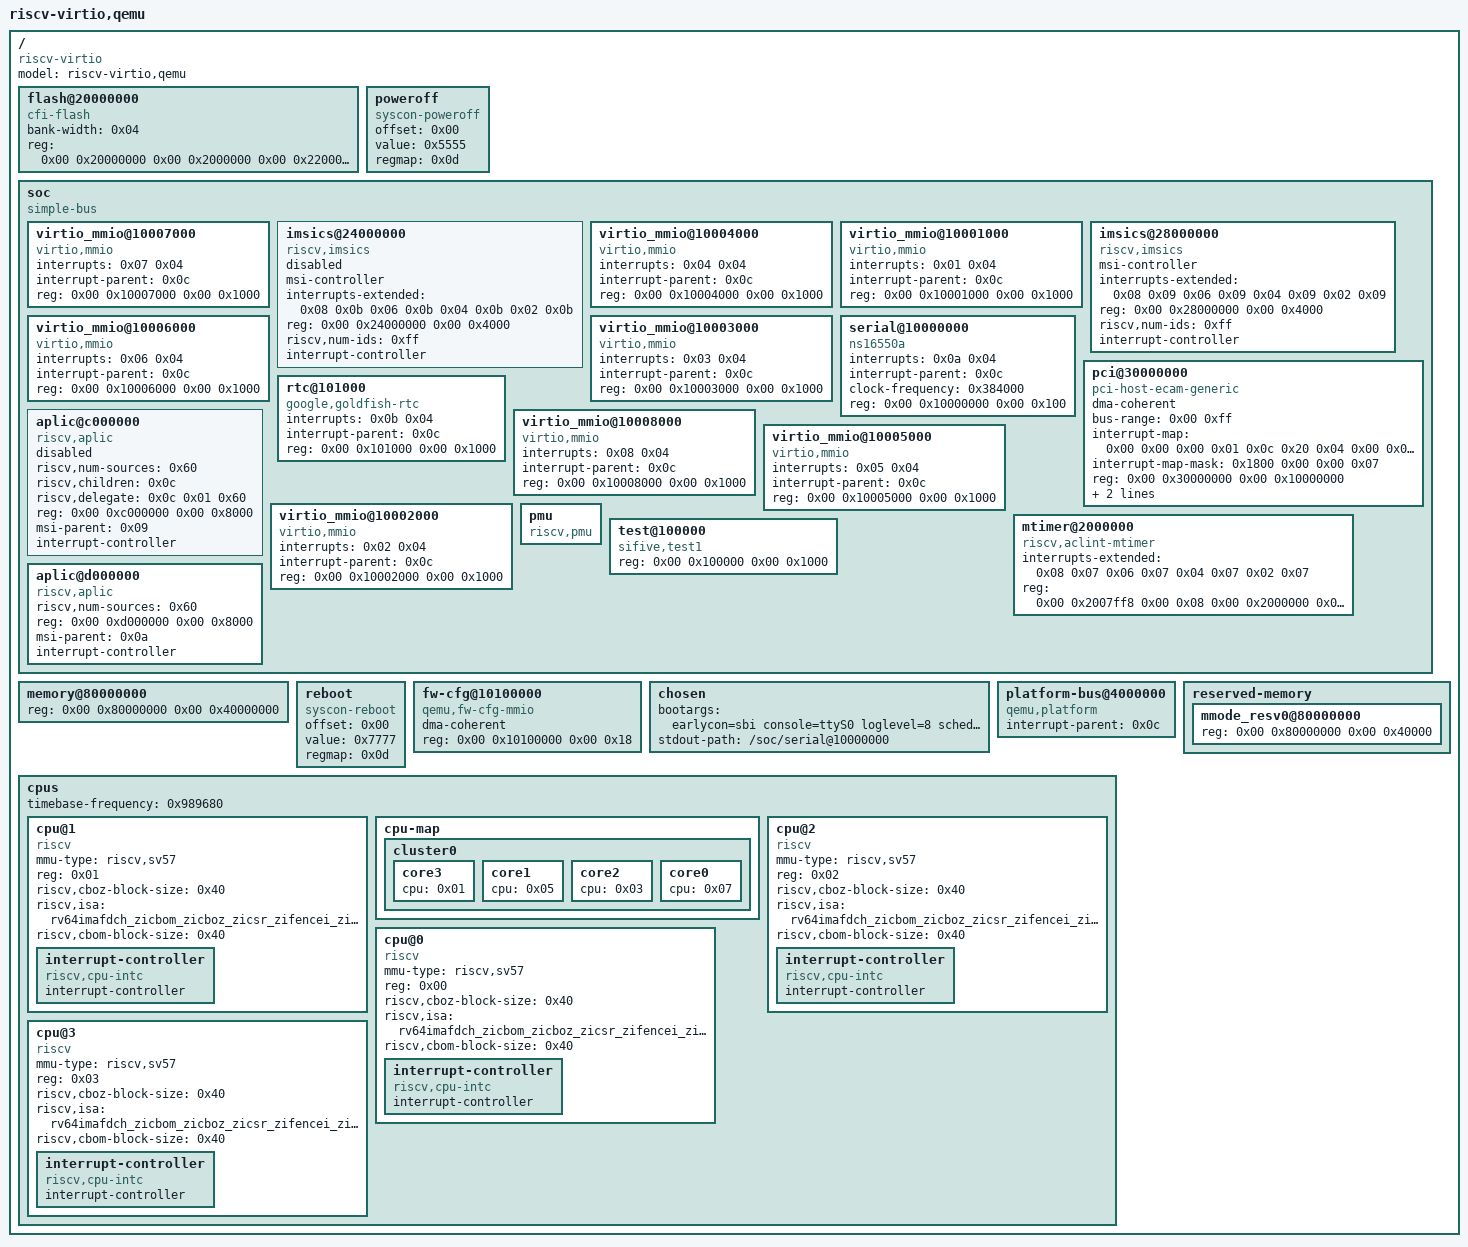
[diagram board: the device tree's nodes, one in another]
/dts-v1/;

/ {
	#address-cells = <0x02>;
	model = "riscv-virtio,qemu";
	#size-cells = <0x02>;
	compatible = "riscv-virtio";

	flash@20000000 {
		bank-width = <0x04>;
		compatible = "cfi-flash";
		reg = <0x00 0x20000000 0x00 0x2000000 0x00 0x22000000 0x00 0x2000000>;
	};

	poweroff {
		offset = <0x00>;
		compatible = "syscon-poweroff";
		value = <0x5555>;
		regmap = <0x0d>;
	};

	soc {
		#address-cells = <0x02>;
		#size-cells = <0x02>;
		compatible = "simple-bus";
		ranges;

		virtio_mmio@10007000 {
			interrupts = <0x07 0x04>;
			interrupt-parent = <0x0c>;
			compatible = "virtio,mmio";
			reg = <0x00 0x10007000 0x00 0x1000>;
		};

		imsics@24000000 {
			msi-controller;
			interrupts-extended = <0x08 0x0b 0x06 0x0b 0x04 0x0b 0x02 0x0b>;
			compatible = "riscv,imsics";
			#interrupt-cells = <0x00>;
			status = "disabled";
			reg = <0x00 0x24000000 0x00 0x4000>;
			riscv,num-ids = <0xff>;
			phandle = <0x09>;
			interrupt-controller;
		};

		virtio_mmio@10004000 {
			interrupts = <0x04 0x04>;
			interrupt-parent = <0x0c>;
			compatible = "virtio,mmio";
			reg = <0x00 0x10004000 0x00 0x1000>;
		};

		virtio_mmio@10001000 {
			interrupts = <0x01 0x04>;
			interrupt-parent = <0x0c>;
			compatible = "virtio,mmio";
			reg = <0x00 0x10001000 0x00 0x1000>;
		};

		imsics@28000000 {
			msi-controller;
			interrupts-extended = <0x08 0x09 0x06 0x09 0x04 0x09 0x02 0x09>;
			compatible = "riscv,imsics";
			#interrupt-cells = <0x00>;
			reg = <0x00 0x28000000 0x00 0x4000>;
			riscv,num-ids = <0xff>;
			phandle = <0x0a>;
			interrupt-controller;
		};

		virtio_mmio@10006000 {
			interrupts = <0x06 0x04>;
			interrupt-parent = <0x0c>;
			compatible = "virtio,mmio";
			reg = <0x00 0x10006000 0x00 0x1000>;
		};

		virtio_mmio@10003000 {
			interrupts = <0x03 0x04>;
			interrupt-parent = <0x0c>;
			compatible = "virtio,mmio";
			reg = <0x00 0x10003000 0x00 0x1000>;
		};

		serial@10000000 {
			interrupts = <0x0a 0x04>;
			interrupt-parent = <0x0c>;
			clock-frequency = <0x384000>;
			compatible = "ns16550a";
			reg = <0x00 0x10000000 0x00 0x100>;
		};

		pci@30000000 {
			#address-cells = <0x03>;
			dma-coherent;
			bus-range = <0x00 0xff>;
			interrupt-map = <0x00 0x00 0x00 0x01 0x0c 0x20 0x04 0x00 0x00 0x00 0x02 0x0c 0x21 0x04 0x00 0x00 0x00 0x03 0x0c 0x22 0x04 0x00 0x00 0x00 0x04 0x0c 0x23 0x04 0x800 0x00 0x00 0x01 0x0c 0x21 0x04 0x800 0x00 0x00 0x02 0x0c 0x22 0x04 0x800 0x00 0x00 0x03 0x0c 0x23 0x04 0x800 0x00 0x00 0x04 0x0c 0x20 0x04 0x1000 0x00 0x00 0x01 0x0c 0x22 0x04 0x1000 0x00 0x00 0x02 0x0c 0x23 0x04 0x1000 0x00 0x00 0x03 0x0c 0x20 0x04 0x1000 0x00 0x00 0x04 0x0c 0x21 0x04 0x1800 0x00 0x00 0x01 0x0c 0x23 0x04 0x1800 0x00 0x00 0x02 0x0c 0x20 0x04 0x1800 0x00 0x00 0x03 0x0c 0x21 0x04 0x1800 0x00 0x00 0x04 0x0c 0x22 0x04>;
			#size-cells = <0x02>;
			device_type = "pci";
			interrupt-map-mask = <0x1800 0x00 0x00 0x07>;
			compatible = "pci-host-ecam-generic";
			ranges = <0x1000000 0x00 0x00 0x00 0x3000000 0x00 0x10000 0x2000000 0x00 0x40000000 0x00 0x40000000 0x00 0x40000000 0x3000000 0x04 0x00 0x04 0x00 0x04 0x00>;
			#interrupt-cells = <0x01>;
			reg = <0x00 0x30000000 0x00 0x10000000>;
			linux,pci-domain = <0x00>;
			msi-parent = <0x0a>;
		};

		rtc@101000 {
			interrupts = <0x0b 0x04>;
			interrupt-parent = <0x0c>;
			compatible = "google,goldfish-rtc";
			reg = <0x00 0x101000 0x00 0x1000>;
		};

		aplic@c000000 {
			riscv,num-sources = <0x60>;
			riscv,children = <0x0c>;
			compatible = "riscv,aplic";
			#interrupt-cells = <0x02>;
			status = "disabled";
			riscv,delegate = <0x0c 0x01 0x60>;
			reg = <0x00 0xc000000 0x00 0x8000>;
			phandle = <0x0b>;
			msi-parent = <0x09>;
			interrupt-controller;
		};

		virtio_mmio@10008000 {
			interrupts = <0x08 0x04>;
			interrupt-parent = <0x0c>;
			compatible = "virtio,mmio";
			reg = <0x00 0x10008000 0x00 0x1000>;
		};

		virtio_mmio@10005000 {
			interrupts = <0x05 0x04>;
			interrupt-parent = <0x0c>;
			compatible = "virtio,mmio";
			reg = <0x00 0x10005000 0x00 0x1000>;
		};

		virtio_mmio@10002000 {
			interrupts = <0x02 0x04>;
			interrupt-parent = <0x0c>;
			compatible = "virtio,mmio";
			reg = <0x00 0x10002000 0x00 0x1000>;
		};

		pmu {
			compatible = "riscv,pmu";
		};

		mtimer@2000000 {
			interrupts-extended = <0x08 0x07 0x06 0x07 0x04 0x07 0x02 0x07>;
			compatible = "riscv,aclint-mtimer";
			reg = <0x00 0x2007ff8 0x00 0x08 0x00 0x2000000 0x00 0x7ff8>;
		};

		test@100000 {
			compatible = "sifive,test1\0sifive,test0\0syscon";
			reg = <0x00 0x100000 0x00 0x1000>;
			phandle = <0x0d>;
		};

		aplic@d000000 {
			riscv,num-sources = <0x60>;
			compatible = "riscv,aplic";
			#interrupt-cells = <0x02>;
			reg = <0x00 0xd000000 0x00 0x8000>;
			phandle = <0x0c>;
			msi-parent = <0x0a>;
			interrupt-controller;
		};
	};

	memory@80000000 {
		device_type = "memory";
		reg = <0x00 0x80000000 0x00 0x40000000>;
	};

	reboot {
		offset = <0x00>;
		compatible = "syscon-reboot";
		value = <0x7777>;
		regmap = <0x0d>;
	};

	fw-cfg@10100000 {
		dma-coherent;
		compatible = "qemu,fw-cfg-mmio";
		reg = <0x00 0x10100000 0x00 0x18>;
	};

	chosen {
		bootargs = "earlycon=sbi console=ttyS0 loglevel=8 sched_debug root=/dev/vda rootfstype=ext4 rw ";
		stdout-path = "/soc/serial@10000000";
	};

	platform-bus@4000000 {
		#address-cells = <0x01>;
		#size-cells = <0x01>;
		interrupt-parent = <0x0c>;
		compatible = "qemu,platform\0simple-bus";
		ranges = <0x00 0x00 0x4000000 0x2000000>;
	};

	cpus {
		#address-cells = <0x01>;
		#size-cells = <0x00>;
		timebase-frequency = <0x989680>;

		cpu@1 {
			device_type = "cpu";
			compatible = "riscv";
			mmu-type = "riscv,sv57";
			status = "okay";
			reg = <0x01>;
			phandle = <0x05>;
			riscv,cboz-block-size = <0x40>;
			riscv,isa = "rv64imafdch_zicbom_zicboz_zicsr_zifencei_zihintpause_zawrs_zca_zcd_zba_zbb_zbc_zbs_smaia_ssaia_sstc_svadu";
			riscv,cbom-block-size = <0x40>;

			interrupt-controller {
				compatible = "riscv,cpu-intc";
				#interrupt-cells = <0x01>;
				phandle = <0x06>;
				interrupt-controller;
			};
		};

		cpu-map {

			cluster0 {

				core3 {
					cpu = <0x01>;
				};

				core1 {
					cpu = <0x05>;
				};

				core2 {
					cpu = <0x03>;
				};

				core0 {
					cpu = <0x07>;
				};
			};
		};

		cpu@2 {
			device_type = "cpu";
			compatible = "riscv";
			mmu-type = "riscv,sv57";
			status = "okay";
			reg = <0x02>;
			phandle = <0x03>;
			riscv,cboz-block-size = <0x40>;
			riscv,isa = "rv64imafdch_zicbom_zicboz_zicsr_zifencei_zihintpause_zawrs_zca_zcd_zba_zbb_zbc_zbs_smaia_ssaia_sstc_svadu";
			riscv,cbom-block-size = <0x40>;

			interrupt-controller {
				compatible = "riscv,cpu-intc";
				#interrupt-cells = <0x01>;
				phandle = <0x04>;
				interrupt-controller;
			};
		};

		cpu@0 {
			device_type = "cpu";
			compatible = "riscv";
			mmu-type = "riscv,sv57";
			status = "okay";
			reg = <0x00>;
			phandle = <0x07>;
			riscv,cboz-block-size = <0x40>;
			riscv,isa = "rv64imafdch_zicbom_zicboz_zicsr_zifencei_zihintpause_zawrs_zca_zcd_zba_zbb_zbc_zbs_smaia_ssaia_sstc_svadu";
			riscv,cbom-block-size = <0x40>;

			interrupt-controller {
				compatible = "riscv,cpu-intc";
				#interrupt-cells = <0x01>;
				phandle = <0x08>;
				interrupt-controller;
			};
		};

		cpu@3 {
			device_type = "cpu";
			compatible = "riscv";
			mmu-type = "riscv,sv57";
			status = "okay";
			reg = <0x03>;
			phandle = <0x01>;
			riscv,cboz-block-size = <0x40>;
			riscv,isa = "rv64imafdch_zicbom_zicboz_zicsr_zifencei_zihintpause_zawrs_zca_zcd_zba_zbb_zbc_zbs_smaia_ssaia_sstc_svadu";
			riscv,cbom-block-size = <0x40>;

			interrupt-controller {
				compatible = "riscv,cpu-intc";
				#interrupt-cells = <0x01>;
				phandle = <0x02>;
				interrupt-controller;
			};
		};
	};

	reserved-memory {
		#address-cells = <0x02>;
		#size-cells = <0x02>;
		ranges;

		mmode_resv0@80000000 {
			reg = <0x00 0x80000000 0x00 0x40000>;
		};
	};
};
